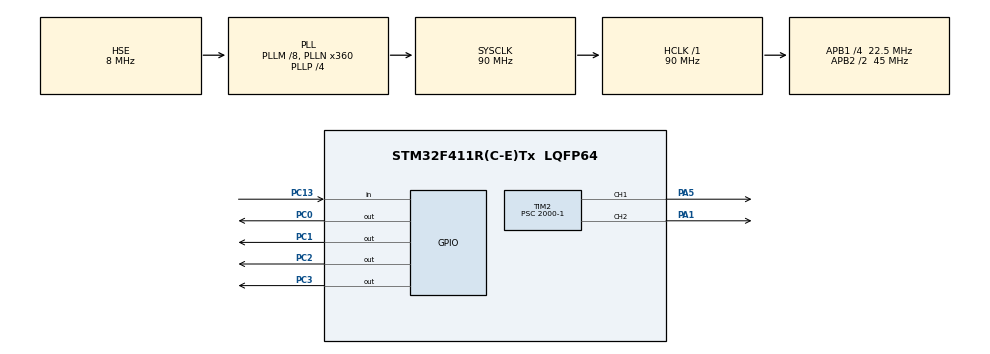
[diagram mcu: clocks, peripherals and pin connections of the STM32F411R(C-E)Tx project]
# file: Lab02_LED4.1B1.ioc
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Mcu.Family=STM32F4
Mcu.Name=STM32F411R(C-E)Tx
Mcu.Package=LQFP64
NVIC.PriorityGroup=NVIC_PRIORITYGROUP_4
PA1.Signal=S_TIM2_CH2
PA5.Signal=S_TIM2_CH1_ETR
PC0.GPIO_Speed=GPIO_SPEED_FREQ_LOW
PC0.Signal=GPIO_Output
PC1.GPIO_Speed=GPIO_SPEED_FREQ_LOW
PC1.Signal=GPIO_Output
PC13-ANTI_TAMP.Signal=GPIO_Input
PC2.GPIO_Speed=GPIO_SPEED_FREQ_LOW
PC2.Signal=GPIO_Output
PC3.Signal=GPIO_Output
PH0\ -\ OSC_IN.Mode=HSE-External-Oscillator
PH0\ -\ OSC_IN.Signal=RCC_OSC_IN
PH1\ -\ OSC_OUT.Mode=HSE-External-Oscillator
PH1\ -\ OSC_OUT.Signal=RCC_OSC_OUT
ProjectManager.HeapSize=0x200
ProjectManager.StackSize=0x400
ProjectManager.TargetToolchain=MDK-ARM V5
RCC.48MHZClocksFreq_Value=90000000
RCC.AHBFreq_Value=90000000
RCC.APB1CLKDivider=RCC_HCLK_DIV4
RCC.APB1Freq_Value=22500000
RCC.APB1TimFreq_Value=45000000
RCC.APB2CLKDivider=RCC_HCLK_DIV2
RCC.APB2Freq_Value=45000000
RCC.APB2TimFreq_Value=90000000
RCC.CortexFreq_Value=90000000
RCC.HCLKFreq_Value=90000000
RCC.HSE_VALUE=8000000
RCC.HSI_VALUE=16000000
RCC.LSE_VALUE=32768
RCC.PLLM=8
RCC.PLLN=360
RCC.PLLP=RCC_PLLP_DIV4
RCC.PLLSourceVirtual=RCC_PLLSOURCE_HSE
RCC.SYSCLKFreq_VALUE=90000000
RCC.SYSCLKSource=RCC_SYSCLKSOURCE_PLLCLK
RCC.VCOOutputFreq_Value=360000000
SH.S_TIM2_CH1_ETR.0=TIM2_CH1,PWM Generation1 CH1
SH.S_TIM2_CH2.0=TIM2_CH2,PWM Generation2 CH2
TIM2.Channel-PWM\ Generation1\ CH1=TIM_CHANNEL_1
TIM2.Channel-PWM\ Generation2\ CH2=TIM_CHANNEL_2
TIM2.Period=1000-1
TIM2.Prescaler=2000-1
TIM2.Pulse-PWM\ Generation1\ CH1=1000
VP_TIM2_VS_ClockSourceINT.Mode=Internal
board=custom

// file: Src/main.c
/* USER CODE BEGIN Header */
/**
  ******************************************************************************
  * @file           : main.c
  * @brief          : Main program body
  ******************************************************************************
  ** This notice applies to any and all portions of this file
  * that are not between comment pairs USER CODE BEGIN and
  * USER CODE END. Other portions of this file, whether
  * inserted by the user or by software development tools
  * are owned by their respective copyright owners.
  *
  * COPYRIGHT(c) 2019 STMicroelectronics
  *
  * Redistribution and use in source and binary forms, with or without modification,
  * are permitted provided that the following conditions are met:
  *   1. Redistributions of source code must retain the above copyright notice,
  *      this list of conditions and the following disclaimer.
  *   2. Redistributions in binary form must reproduce the above copyright notice,
  *      this list of conditions and the following disclaimer in the documentation
  *      and/or other materials provided with the distribution.
  *   3. Neither the name of STMicroelectronics nor the names of its contributors
  *      may be used to endorse or promote products derived from this software
  *      without specific prior written permission.
  *
  * THIS SOFTWARE IS PROVIDED BY THE COPYRIGHT HOLDERS AND CONTRIBUTORS "AS IS"
  * AND ANY EXPRESS OR IMPLIED WARRANTIES, INCLUDING, BUT NOT LIMITED TO, THE
  * IMPLIED WARRANTIES OF MERCHANTABILITY AND FITNESS FOR A PARTICULAR PURPOSE ARE
  * DISCLAIMED. IN NO EVENT SHALL THE COPYRIGHT HOLDER OR CONTRIBUTORS BE LIABLE
  * FOR ANY DIRECT, INDIRECT, INCIDENTAL, SPECIAL, EXEMPLARY, OR CONSEQUENTIAL
  * DAMAGES (INCLUDING, BUT NOT LIMITED TO, PROCUREMENT OF SUBSTITUTE GOODS OR
  * SERVICES; LOSS OF USE, DATA, OR PROFITS; OR BUSINESS INTERRUPTION) HOWEVER
  * CAUSED AND ON ANY THEORY OF LIABILITY, WHETHER IN CONTRACT, STRICT LIABILITY,
  * OR TORT (INCLUDING NEGLIGENCE OR OTHERWISE) ARISING IN ANY WAY OUT OF THE USE
  * OF THIS SOFTWARE, EVEN IF ADVISED OF THE POSSIBILITY OF SUCH DAMAGE.
  *
  ******************************************************************************
  */
/* USER CODE END Header */

#include "main.h"
#include "tim.h"
#include "gpio.h"

void SystemClock_Config(void);

int main(void)
{

  /* MCU Configuration--------------------------------------------------------*/

  /* Reset of all peripherals, Initializes the Flash interface and the Systick. */
  HAL_Init();

  /* Configure the system clock */
  SystemClock_Config();

  /* Initialize all configured peripherals */
  MX_GPIO_Init();
  MX_TIM2_Init();
  /* USER CODE BEGIN 2 */
	HAL_TIM_PWM_Start(&htim2, TIM_CHANNEL_1);
	HAL_TIM_PWM_Start(&htim2, TIM_CHANNEL_2);
  /* USER CODE END 2 */

  /* Infinite loop */
  while (1)
  {

    /* USER CODE BEGIN 3 */
		if (HAL_GPIO_ReadPin(GPIOC, GPIO_PIN_13) == GPIO_PIN_RESET)
		{
			TIM2->CCR1 = 0x7777;
			TIM2->CCR2 = 0x7777;

			HAL_GPIO_WritePin(GPIOC, GPIO_PIN_0, GPIO_PIN_SET);
			HAL_GPIO_WritePin(GPIOC, GPIO_PIN_1, GPIO_PIN_RESET);
			HAL_GPIO_WritePin(GPIOC, GPIO_PIN_2, GPIO_PIN_RESET);
			HAL_GPIO_WritePin(GPIOC, GPIO_PIN_3, GPIO_PIN_SET);

		}
	}
  /* USER CODE END 3 */
}

void SystemClock_Config(void)
{
  RCC_OscInitTypeDef RCC_OscInitStruct = {0};
  RCC_ClkInitTypeDef RCC_ClkInitStruct = {0};

  /**Configure the main internal regulator output voltage
  */
  __HAL_RCC_PWR_CLK_ENABLE();
  __HAL_PWR_VOLTAGESCALING_CONFIG(PWR_REGULATOR_VOLTAGE_SCALE1);
  /**Initializes the CPU, AHB and APB busses clocks
  */
  RCC_OscInitStruct.OscillatorType = RCC_OSCILLATORTYPE_HSE;
  RCC_OscInitStruct.HSEState = RCC_HSE_ON;
  RCC_OscInitStruct.PLL.PLLState = RCC_PLL_ON;
  RCC_OscInitStruct.PLL.PLLSource = RCC_PLLSOURCE_HSE;
  RCC_OscInitStruct.PLL.PLLM = 8;
  RCC_OscInitStruct.PLL.PLLN = 360;
  RCC_OscInitStruct.PLL.PLLP = RCC_PLLP_DIV4;
  RCC_OscInitStruct.PLL.PLLQ = 4;
  if (HAL_RCC_OscConfig(&RCC_OscInitStruct) != HAL_OK)
  {
    Error_Handler();
  }
  /**Initializes the CPU, AHB and APB busses clocks
  */
  RCC_ClkInitStruct.ClockType = RCC_CLOCKTYPE_HCLK|RCC_CLOCKTYPE_SYSCLK
                              |RCC_CLOCKTYPE_PCLK1|RCC_CLOCKTYPE_PCLK2;
  RCC_ClkInitStruct.SYSCLKSource = RCC_SYSCLKSOURCE_PLLCLK;
  RCC_ClkInitStruct.AHBCLKDivider = RCC_SYSCLK_DIV1;
  RCC_ClkInitStruct.APB1CLKDivider = RCC_HCLK_DIV4;
  RCC_ClkInitStruct.APB2CLKDivider = RCC_HCLK_DIV2;

  if (HAL_RCC_ClockConfig(&RCC_ClkInitStruct, FLASH_LATENCY_2) != HAL_OK)
  {
    Error_Handler();
  }
}

void Error_Handler(void)
{
}

/************************ (C) COPYRIGHT STMicroelectronics *****END OF FILE****/
